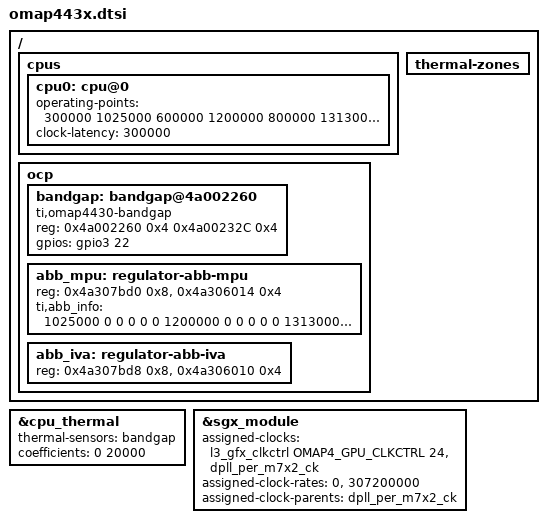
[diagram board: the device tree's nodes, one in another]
#include "omap4.dtsi"
/ {
	cpus {
		cpu0: cpu@0 {
			operating-points = <
				300000  1025000
				600000  1200000
				800000  1313000
				1008000 1375000
			>;
			clock-latency = <300000>;  
			#cooling-cells = <2>;  
		};
	};
	thermal-zones {
		#include "omap4-cpu-thermal.dtsi"
	};
	ocp {
		bandgap: bandgap@4a002260 {
			reg = <0x4a002260 0x4
			       0x4a00232C 0x4>;
			compatible = "ti,omap4430-bandgap";
			gpios = <&gpio3 22 GPIO_ACTIVE_HIGH>;
			#thermal-sensor-cells = <0>;
		};
	};
	ocp {
		abb_mpu: regulator-abb-mpu {
			status = "okay";
			reg = <0x4a307bd0 0x8>, <0x4a306014 0x4>;
			reg-names = "base-address", "int-address";
			ti,abb_info = <
			1025000		0	0	0	0	0
			1200000		0	0	0	0	0
			1313000		0	0	0	0	0
			1375000		1	0	0	0	0
			1389000		1	0	0	0	0
			>;
		};
		abb_iva: regulator-abb-iva {
			reg = <0x4a307bd8 0x8>, <0x4a306010 0x4>;
			reg-names = "base-address", "int-address";
		};
	};
};
&cpu_thermal {
	thermal-sensors = <&bandgap>;
	coefficients = <0 20000>;
};
/include/ "omap443x-clocks.dtsi"
&sgx_module {
	assigned-clocks = <&l3_gfx_clkctrl OMAP4_GPU_CLKCTRL 24>,
			  <&dpll_per_m7x2_ck>;
	assigned-clock-rates = <0>, <307200000>;
	assigned-clock-parents = <&dpll_per_m7x2_ck>;
};
